# USB0_VBP2APB_WRAP_CONTROLLER_VBP_CORE_ADDR_MAP register map
Vendor: Texas Instruments
Peripheral module from a debugger description file (folder J721S2).
Registers are 32-bit, access per field, reset 0x0 unless marked. A register's access mark holds for its fields unless they carry their own. Offsets are as the file gives them; lines under a group give offsets from that group; [hi:lo] are bit positions; {n}, {i} and the like mark numbered series; 'fields as' and 'values as' point back to an identical list; <NAME> marks a mode.

## USB0_VBP2APB_WRAP_CONTROLLER_VBP_CORE_ADDR_MAP (part 1 of 9)
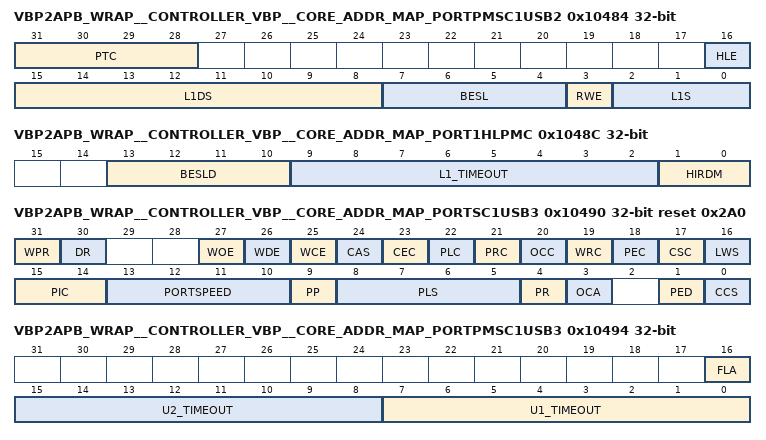
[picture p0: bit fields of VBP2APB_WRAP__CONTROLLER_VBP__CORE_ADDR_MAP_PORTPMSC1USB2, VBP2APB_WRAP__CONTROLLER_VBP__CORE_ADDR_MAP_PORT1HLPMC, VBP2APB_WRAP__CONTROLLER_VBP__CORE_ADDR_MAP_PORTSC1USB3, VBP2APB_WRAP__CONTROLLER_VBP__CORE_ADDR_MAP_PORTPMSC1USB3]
0x10484 VBP2APB_WRAP__CONTROLLER_VBP__CORE_ADDR_MAP_PORTPMSC1USB2 — The USB2 Port Power Management Status and Control register. Provides the USB2 LPM parameters necessary for the xHC to generate a LPM Token to the downstream device. This register may be read from or written to at any time, including whilst the CNR field in the USBSTS register is high.
  [31:28] PTC rw — Port Test Control, RW. Default = '0'. When this field is '0', the port is NOT operating in a test mode. A non-zero value indicates that it is operating in test mode and the specific test mode is indicated by the specific value. A non-zero Port Test Control value is only valid to a port that is in the Powered-Off state [PLS = Disabled]. If the port is not in this state, the xHC shall respond with the Port Test Control field set to Port Test Control Error. Refer to section 4.19.6 for the operational model for using these test modes. The encoding of the Test Mode bits for a USB2 protocol port are: 0: Test mode not enabled 1: Test J_STATE 2: Test K_STATE 3: Test SE0_NAK 4: Test Packet 5: Test FORCE_ENABLE 6-14: Reserved. 15: Port Test Control Error. Refer to the sections 7.1.20 and 11.24.2.13 of the USB2 spec for more information on Test Modes.
  [16] HLE rw — Hardware LPM Enable [HLE], RW. Default = '0'. If this bit is set to '1', then hardware controlled LPM shall be enabled for this port. Refer to section 4.23.5.1.1.1 of xHCI specification. If the USB2 Hardware LPM Capability is not supported [HLC = '0'] this field shall be RsvdZ.
  [15:8] L1DS rw — L1 Device Slot, RW. Default = 0. System software sets this field to indicate the ID of the Device Slot associated with the device directly attached to the Root Hub port. A value of '0' indicates no device is present. The xHC uses this field to lookup information necessary to generate the LPM Token packet.
  [7:4] BESL rw — Best Effort Service Latency [BESL], RW. Default = 0. System software sets this field to indicate to the recipient device how long the xHC will drive resume if it [the xHC] initiates an exit from L1. The BESL value encoding is defined in Table 13. Note that the BESL field is used by both software and hardware controlled LPM. Refer to section 4.23.5.1.1 of xHCI specification for more information on BESL use. Refer to section 5.2.5 of xHCI specification for information on how DBESL may be used to establish an initial value for BESL.
  [3] RWE rw — Remote Wake Enable [RWE], RW. Default = '0'. System software sets this flag to enable or disable the device for remote wake from L1. The value of this flag shall temporarily [while in L1] override the current setting of the Remote Wake feature set by the standard Set/ClearFeature[] commands defined in Universal Serial Bus Specification, revision 2.0, Chapter 9.
  [2:0] L1S ro — L1 Status [L1S], RO. Default = 0. This field is used by software to determine whether an L1-based suspend request [LPM transaction] was successful, specifically: 0: Invalid - This field shall be ignored by software. 1: Success - Port successfully transitioned to L1 [ACK] 2: Not Yet - Device is unable to enter L1 at this time [NYET] 3: Not Supported - Device does not support L1 transitions [STALL] 4: Timeout/Error - Device failed to respond to the LPM Transaction or an error occurred 5-7: Reserved The value of this field is only valid when the port resides in the L0 or L1 state [PLS = 0 or 2]. Refer to section 4.23.5.1.1 of xHCI specification for more information.
0x10488 VBP2APB_WRAP__CONTROLLER_VBP__CORE_ADDR_MAP_RSVDP1USB2 ro — Reserved and Preserved: Reserved for future RW implementations. Software shall preserve the value read for writes to bits.
0x1048C VBP2APB_WRAP__CONTROLLER_VBP__CORE_ADDR_MAP_PORT1HLPMC — The optional normative USB2 Port Hardware LPM Control register provides the USB2 LPM parameters necessary for the xHC to automatically generate a LPM Token to the downstream device. Refer to section 4.23.5.1.1.1 of xHCI specification for more information. This register may be read from or written to at any time, including whilst the CNR field in the USBSTS register is high.
  [13:10] BESLD rw — Best Effort Service Latency Deep [BESLD], RWS. Default = '0'. System software sets this field to indicate to the recipient device how long the xHC will drive resume on an exit from U2. Refer to section 4.23.5.1.1.1 of xHCI specification for more information on BESLD use. The BESLD value encoding is defined in Table 13. Refer to section 5.2.6 of xHCI specification for information on how DBESLD may be used to establish an initial value for BESLD.
  [9:2] L1_TIMEOUT rw — L1 Timeout, RWS. Default = 00h. Timeout value for the L1 inactivity timer [LPM Timer]. This field shall be set to 00h by the assertion of PR to '1'. Refer to section 4.23.5.1.1.1 of xHci specification for more information on L1 Timeout operation. The following are permissible values: 00h 128 us. [default] 01h 256 us. 02h 512 us. 03h 768 us. ... FFh 65,280 us.
  [1:0] HIRDM rw — Host Initiated Resume Duration Mode [HIRDM], RWS. Default = 0h. Indicates which HIRD value should be used. The following are permissible values: 0: Initiate L1 using BESL only on timeout. [default] 1: Initiate L1 using BESLD on timeout. If rejected by device, initiate L1 using BESL. 3-2: Reserved.
0x10490 VBP2APB_WRAP__CONTROLLER_VBP__CORE_ADDR_MAP_PORTSC1USB3 access not given reset 0x2A0 — Port Status and Control Register for USB3 protocol port. The register cannot be accessed if USB3 PHY is not active (i.e. when there is no USB3 PHY or when USB3 PHY has not started providing USB3 PIPE PCLK after reset).
  [31] WPR — Warm Port Reset [WPR], RW1S. Default = '0'. When software writes a '1' to this bit, the Warm Reset sequence as defined in the USB3 Specification is initiated and the PR flag is set to '1'. Once initiated, the PR, PRC, and WRC flags shall reflect the progress of the Warm Reset sequence. This flag shall always return 0 when read. Refer to section 4.19.5.1 of xHCI specification. (access R/W1TS)
  [30] DR ro — Device Removable [DR], RO. This flag indicates if this port has a removable device attached. '0' = Device is removable. '1' = Device is non-removable.
  [27] WOE rw — Wake on Over-current Enable [WOE], RWS. Default = '0'. Writing this bit to a '1' enables the port to be sensitive to over-current conditions as system wake-up events. Refer to section 4.15 of xHCI specification for operational model.
  [26] WDE rw — Wake on Disconnect Enable [WDE], RWS. Default = '0'. Writing this bit to a '1' enables the port to be sensitive to device disconnects as system wake-up events. Refer to section 4.15 of xHCI specification for operational model.
  [25] WCE rw — Wake on Connect Enable [WCE], RWS. Default = '0'. Writing this bit to a '1' enables the port to be sensitive to device connects as system wake-up events. Refer to section 4.15 of xHCI specification for operational model.
  [24] CAS ro — Cold Attach Status [CAS], RO. Default = '0'. '1' = Far-end Receiver Terminations were detected in the Disconnected state and the Root Hub Port State Machine was unable to advance to the Enabled state. Refer to sections 4.19.8 of xHCI specification for more details on the Cold Attach Status [CAS] assertion conditions. Software shall clear this bit by writing a '1' to WPR or the xHC shall clear this bit if CCS transitions to '1'. This flag is 0 if PP is 0 or for USB2 protocol ports. Note: Additionally to the xHCI spec the CAS may be set in D1/D2 state. If customer's PLL lock time ensures finishing LFPS in tPollingLFPSTimeout [360ms] the SW driver may ignore the CAS and wait for PORTSC.CCS. It prevents additional reset on USB port. However, handling CAS in normal way should not have any negative impact on the device.
  [23] CEC — Port Config Error Change [CEC], RW1CS. Default = '0'. This flag indicates that the port failed to configure its link partner. '0' = No change. '1' = Port Config Error detected. Software shall clear this bit by writing a '1' to it. Refer to section 4.19.2 of xHCI specification for more information on change bit usage. (access R/W1TC)
  [22] PLC — Port Link State Change [PLC], RW1CS. Default = '0'. This flag is set to '1' due to the following PLS transitions: U3 -> Resume [Wakeup signaling from a device], Resume -> Recovery -> U0 [Device Resume complete [USB3 protocol ports only]], Resume -> U0 [Device Resume complete [USB2 protocol ports only]], U3 -> Recovery -> U0 [Software Resume complete [USB3 protocol ports only]], U3 -> U0 [Software Resume complete [USB2 protocol ports only]], U2 -> U0 [L1 Resume complete [USB2 protocol ports only]], U0 -> U0 [L1 Entry Reject [USB2 protocol ports only]], Any state -> Inactive [Error [USB3 protocol ports only]]. Note that this flag shall not be set if the PLS transition was due to software setting PP to 0. Refer to section 4.23.5 of xHCI specification for more information. '0' = No change. '1' = Link Status Changed. Software shall clear this bit by writing a '1' to it. Refer to PLC Condition: references in section 4.19.1 for the specific port state transitions that set this flag. Refer to section 4.19.2 of xHCI specification for more information on change bit usage. (access R/W1TC)
  [21] PRC — Port Reset Change [PRC], RW1CS. Default = '0'. This flag is set to '1' due to a '1' to '0' transition of Port Reset [PR], e.g. when any reset processing [Warm or Hot] on this port is complete. Note that this flag shall not be set to '1' if the reset processing was forced to terminate due to software clearing PP or PED to '0'. '0' = No change. '1' = Reset complete. Software shall clear this bit by writing a '1' to it. Refer to section 4.19.5 of xHCI specification. Refer to section 4.19.2 of xHCI specification for more information on change bit usage. (access R/W1TC)
  [20] OCC — Over-current Change [OCC], RW1CS. Default = '0'. This bit shall be set to a '1' when there is a '0' to '1' or '1' to '0' transition of Over-current Active [OCA]. Software shall clear this bit by writing a '1' to it. Refer to section 4.19.2 of xHCI specification for more information on change bit usage. (access R/W1TC)
  [19] WRC — Warm Port Reset Change [WRC], RW1CS. Default = '0'. This bit is set when Warm Reset processing on this port completes. '0' = No change. '1' = Warm Reset complete. Note that this flag shall not be set to '1' if the Warm Reset processing was forced to terminate due to software clearing PP or PED to '0'. Software shall clear this bit by writing a '1' to it. Refer to section 4.19.5.1 of xHCI specification. Refer to section 4.19.2 of xHCI specification for more information on change bit usage. (access R/W1TC)
  [18] PEC — Port Enabled/Disabled Change [PEC], RW1CS. Default = '0'. '1' = change in PED. '0' = No change. Note that this flag shall not be set if the PED transition was due to software setting PP to '0'. Software shall clear this bit by writing a '1' to it. Refer to section 4.19.2 of xHCI specification for more information on change bit usage. This bit shall never be set to '1'. (access R/W1TC)
  [17] CSC — Connect Status Change [CSC], RW1CS. Default = '0'. '1' = Change in CCS. '0' = No change. This flag indicates a change has occurred in the ports Current Connect Status [CCS] or Cold Attach Status [CAS] bits. Note that this flag shall not be set if the CCS transition was due to software setting PP to '0', or the CAS transition was due to software setting WPR to '1'. The xHC sets this bit to '1' for all changes to the port device connect status, even if system software has not cleared an existing Connect Status Change. For example, the insertion status changes twice before system software has cleared the changed condition, root hub hardware will be setting an already-set bit [i.e., the bit will remain 1]. Software shall clear this bit by writing a '1' to it. Refer to section 4.19.2 of xHCI specification for more information on change bit usage. (access R/W1TC)
  [16] LWS rw — Port Link State Write Strobe [LWS], RW. Default = '0'. When this bit is set to '1' on a write reference to this register, this flag enables writes to the PLS field. When '0', write data in PLS field is ignored. Reads to this bit return '0'.
  [15:14] PIC rw — Port Indicator Control [PIC], RWS. Default = '0'. Writing to these bits has no effect if the Port Indicators [PIND] bit in the HCCPARAMS register is a '0'. If PIND bit is a '1', then the bit encodings are: 0: Port indicators are off, 1: Amber, 2: Green, 3: Undefined. This field is '0' if PP is '0'.
  [13:10] PORTSPEED ro — Port Speed [Port Speed], ROS. Default = '0'. This field identifies the speed of the connected USB Device. This field is only relevant if a device is connected [CCS = '1'] in all other cases this field shall indicate Undefined Speed. Possible values: 0: Undefined Speed 1-15: Protocol Speed ID [PSI], refer to section 7.2.1 of xHCI specification for the definition of PSIV field in the PSI Dword.
  [9] PP rw — Port Power [PP], RWS. Default = '1'. This flag reflects a port's logical, power control state. Because host controllers can implement different methods of port power switching, this flag may or may not represent whether [VBus] power is actually applied to the port. When PP equals a '0' the port is nonfunctional and shall not report attaches, detaches, or Port Link State [PLS] changes. However, the port shall report over-current conditions when PP = '0' if PPC = '0'. After modifying PP, software shall read PP and confirm that it has reached its target state before modifying it again, undefined behavior may occur if this procedure is not followed. '0' = This port is in the Powered-off state. '1' = This port is not in the Powered-off state. If the Port Power Control [PPC] flag in the HCCPARAMS register is '1', then xHC has port power control switches and this bit represents the current setting of the switch ['0' = off, '1'=on]. If the Port Power Control [PPC] flag in the HCCPARAMS register is '0', then xHC does not have port power control switches and each port is hard wired to power, and not affected by this bit. When an over-current condition is detected on a powered port, the xHC shall transition the PP bit in each affected port from a '1' to '0' [removing power from the port]. Refer to section 4.19.4 for more information.
  [8:5] PLS rw — Port Link State [PLS], RWS. Default = RxDetect ['5']. This field is used to power manage the port and reflects its current link state. When the port is in the Enabled state, system software may set the link U state by writing this field. System software may also write this field to force a Disabled to Disconnected state transition of the port. Write Values: 0: The link shall transition to a U0 state from any of the U states. 3: The link shall transition to a U3 state from the U0 state. This action selectively suspends the device connected to this port. While the Port Link State = U3, the hub does not propagate downstream-directed traffic to this port, but the hub shall respond to resume signaling from the port. 5: If the port is in the Disabled state [PLS = Disabled, PP = '1'], then the link shall transition to a RxDetect state and the port shall transition to the Disconnected state, else ignored. 1-2,4,6-15: Ignored. State Encoding: 0: Link is in the U0 State, 1: Link is in the U1 State, 2: Link is in the U2 State, 3: Link is in the U3 State [Device Suspended], 4: Link is in the Disabled State, 5: Link is in the RxDetect State, 6: Link is in the Inactive State, 7: Link is in the Polling State, 8: Link is in the Recovery State, 9: Link is in the Hot Reset State, 10 Link is in the Compliance Mode State, 11: Link is in the Test Mode State, 12-14: Reserved, 15: Link is in the Resume State. Note: The Port Link State Write Strobe [LWS] shall also be set to '1' to write this field. This field is undefined if PP = '0'. Note: Transitions between different states are not reflected until the transition is complete. Refer to section 4.19 of xHCI specification for PLS transition conditions. Refer to sections 4.15.2 and 4.23.5 for more information on the use of this field.
  [4] PR — Port Reset [PR], RW1S. Default = '0'. '1' = Port Reset signaling is asserted. '0' = Port is not in Reset. When software writes a '1' to this bit generating a '0' to '1' transition, the bus reset sequence is initiated. USB3 protocol ports shall execute the Hot Reset sequence as defined in the USB3 Spec. PR remains set until reset signaling is completed by the root hub. This flag is '0' if PP is '0'. (access R/W1TS)
  [3] OCA ro — Over-current Active [OCA], RO. Default = '0'. '1' = This port currently has an over-current condition. '0' = This port does not have an over-current condition. This bit shall automatically transition from a '1' to a '0' when the over-current condition is removed.
  [1] PED — Port Enabled/Disabled [PED], RW1CS. Default = '0'. '1' = Enabled. '0' = Disabled. Ports may only be enabled by the xHC. Software cannot enable a port by writing a '1' to this flag. A port may be disabled by software writing a '1' to this flag. This flag shall automatically be cleared to '0' by a disconnect event or other fault condition. Note that the bit status does not change until the port state actually changes. There may be a delay in disabling or enabling a port due to other host controller or bus events. When the port is disabled [PED = '0'] downstream propagation of data is blocked on this port, except for reset. When the port is in the Polling state [after detecting an attach], the port shall automatically transition to the Enabled state and set PED to '1' upon the completion of successful link training. When the port is in the Disabled state, software shall write a 5 [RxDetect] to the PLS field to transition the port to the Disconnected state. Refer to section 4.19.1.2 of xHCI specification. PED shall automatically be cleared to '0' when PR is set to '1', and set to '1' when PR transitions from '1' to '0' after a successful reset. Refer to Port Reset [PR] bit for more information on how the PED bit is managed. Note that when software writes this bit to a '1', it shall also write a '0' to the PR bit. This flag is '0' if PP is '0'. (access R/W1TC)
  [0] CCS ro — Current Connect Status [CCS], ROS. Default = '0'. '1' = A device is connected to the port. '0' = A device is not connected. This value reflects the current state of the port, and may not correspond directly to the event that caused the Connect Status Change [CSC] bit to be set to '1'. Refer to sections 4.19.3 and 4.19.4 of xHCI specification for more details on the Connect Status Change [CSC] assertion conditions. This flag is '0' if PP is '0'.
0x10494 VBP2APB_WRAP__CONTROLLER_VBP__CORE_ADDR_MAP_PORTPMSC1USB3 — USB3 Port Power Management Status and Control register. Controls the SuperSpeed USB link U-State timeouts. The register cannot be accessed if USB3 PHY is not active (i.e. when there is no USB3 PHY or when USB3 PHY has not started providing USB3 PIPE PCLK after reset).
  [16] FLA rw — Force Link PM Accept [FLA], RW. Default = '0'. When this bit is set to '1', the port shall generate a Set Link Function LMP with the Force_LinkPM_Accept bit asserted ['1']. When this bit is cleared to '0', the port shall generate a Set Link Function LMP with the Force_LinkPM_Accept bit de-asserted ['0']. This flag shall be set to '0' by the assertion of PR to '1' or when CCS = transitions from '0' to '1'. Writes to this flag have no effect if PP = '0'. The Set Link Function LMP is sent by the xHC to the device connected on this port when this bit transitions from '0' to '1' or '1' to '0'. Refer to Sections 8.4.2 and 10.14.2.2 of the USB3 specification for more details. Improper use of the SS Force_LinkPM_Accept functionality can impact the performance of the link significantly. This bit shall only be used for compliance and testing purposes. Software shall ensure that there are no pending packets at the link level before setting this bit. This flag is '0' if PP is '0'.
  [15:8] U2_TIMEOUT rw — U2 Timeout, RWS. Default = 0. Timeout value for U2 inactivity timer. If equal to FFh, the port is disabled from initiating U2 entry. This field shall be set to '0' by the assertion of PR to '1'. Refer to section 4.19.4.1 of xHCI specification for more information on U2 Timeout operation. The following are permissible values: 00h Zero [default] 01h 256 us 02h 512 us ... FEh 65,.024 ms FFh Infinite A U2 Inactivity Timeout LMP shall be sent by the xHC to the device connected on this port when this field is written. Refer to Sections 8.4.3 and 10.4.2.10 of the USB3 specification for more details.
  [7:0] U1_TIMEOUT rw — U1 Timeout, RWS. Default = 0. Timeout value for U1 inactivity timer. If equal to FFh, the port is disabled from initiating U1 entry. This field shall be set to '0' by the assertion of PR to '1'. Refer to section 4.19.4.1 of xHCI specification for more information on U1 Timeout operation. The following are permissible values: 00h Zero [default] 01h 1 us. 02h 2 us. ... 7Fh 127 us. 80h - FEh Reserved FFh Infinite
0x10498 VBP2APB_WRAP__CONTROLLER_VBP__CORE_ADDR_MAP_PORTLI1 ro — The USB3 Port Link Info register reports the Link Error Count.
  [15:0] LEC — Link Error Count, RO. Default = '0'. This field returns the number of link errors detected by the port. This value shall be reset to '0' by the assertion of a Chip Hardware Reset, HCRST, when PR transitions from 1 to 0, or when CCS = transitions from '0' to '1'.
0x1049C VBP2APB_WRAP__CONTROLLER_VBP__CORE_ADDR_MAP_RSVDP1USB3 ro — Reserved and Preserved: Reserved for future RW implementations. Software shall preserve the value read for writes to bits.
0x12000 VBP2APB_WRAP__CONTROLLER_VBP__CORE_ADDR_MAP_MFINDEX ro — This register is used by the system software to determine the current periodic frame. The register value is incremented every 125 microseconds (once each microframe). This register is only incremented while Run/Stop (R/S) = '1'. The value of this register affects the SOF value generated by USB2 Bus Instances.
  [13:0] MFINDEX — Microframe Index, RO. The value in this register increments at the end of each microframe [e.g. 125us.]. Bits [13:3] may be used to determine the current 1ms Frame Index. Note: Setting frindex_wr_en to '1' [bit 31 of XECP_CMDM_CTRL_REG3] enables software writes to this field.
0x12004 VBP2APB_WRAP__CONTROLLER_VBP__CORE_ADDR_MAP_RSVDZ_RT ro — Reserved and Zero: Reserved for future RW1C implementations. Software shall use zero for writes to these bits.
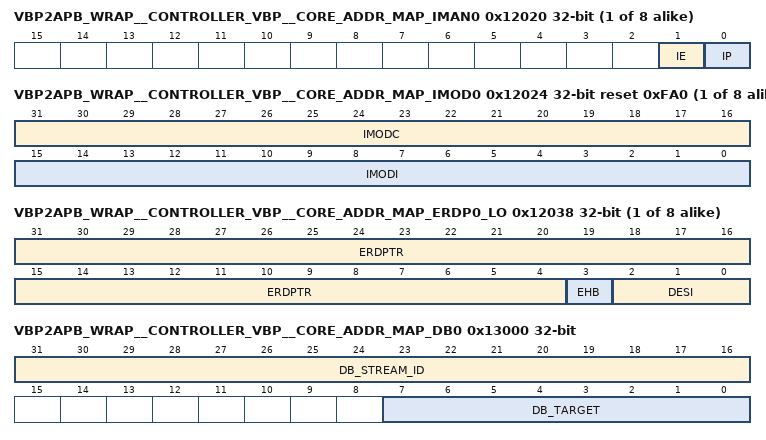
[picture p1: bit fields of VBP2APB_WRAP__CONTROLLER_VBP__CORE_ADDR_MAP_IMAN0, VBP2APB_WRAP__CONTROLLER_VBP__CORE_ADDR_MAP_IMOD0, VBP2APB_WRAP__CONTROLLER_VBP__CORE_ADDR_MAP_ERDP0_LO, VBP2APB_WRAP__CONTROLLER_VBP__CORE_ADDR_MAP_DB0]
{0x12020+0x20*i} VBP2APB_WRAP__CONTROLLER_VBP__CORE_ADDR_MAP_IMAN{i} access not given (i=0..7) — Interrupter Management Register (IMAN). The Interrupter Management register allows system software to enable, disable, detect, and force xHC interrupts.
  [1] IE rw — Interrupt Enable [IE], RW. Default = '0'. This flag specifies whether the Interrupter is capable of generating an interrupt. When this bit and the IP bit are set ['1'], the Interrupter shall generate an interrupt when the Interrupter Moderation Counter reaches 0. If this bit is '0', then the Interrupter is prohibited from generating interrupts.
  [0] IP — Interrupt Pending [IP], RW1C. Default = '0'. This flag represents the current state of the Interrupter. If IP = '1', an interrupt is pending for this Interrupter. A '0' value indicates that no interrupt is pending for the Interrupter. Refer to section 4.17.5 of the xHCI specification for the conditions that modify the state of this flag. (access R/W1TC)
{0x12024+0x20*i} VBP2APB_WRAP__CONTROLLER_VBP__CORE_ADDR_MAP_IMOD{i} rw reset 0xFA0 (i=0..7) — Interrupter Moderation Register (IMOD). The Interrupter Moderation Register controls the interrupt moderation feature of an Interrupter, allowing system software to throttle the interrupt rate generated by the xHC.
  [31:16] IMODC — Interrupt Moderation Counter [IMODC], RW. Default = undefined. Down counter. Loaded with the IMODI value whenever IP is cleared to '0', counts down to 0, and stops. The associated interrupt shall be signaled whenever this counter is zero, the Event Ring is not empty, the IE and IP flags = '1', and EHB = '0'. This counter may be directly written by software at any time to alter the interrupt rate.
  [15:0] IMODI — Interrupt Moderation Interval [IMODI], RW. Default = 'hFA0' [~1ms]. Minimum inter-interrupt interval. The interval is specified in 250ns increments. A value of zero disables interrupt throttling logic and interrupts shall be generated immediately if IP = '0', EHB = '0', and the Event Ring is not empty. The IMODI field shall default to 'hFA0' [1 ms] upon initialization and reset. It may be loaded with an alternative value by software when the Interrupter is initialized.
{0x12028+0x20*i} VBP2APB_WRAP__CONTROLLER_VBP__CORE_ADDR_MAP_ERSTSZ{i} (i=0..7) — Event Ring Segment Table Size Register (ERSTSZ). The Event Ring Segment Table Size Register defines the number of segments supported by the Event Ring Segment Table.
  [15:0] ERSTS rw — Event Ring Segment Table Size, RW. Default = 0. This field identifies the number of valid Event Ring Segment Table entries in the Event Ring Segment Table pointed to by the Event Ring Segment Table Base Address register. The maximum value supported by an xHC implementation for this register is defined by the ERST Max field in the HCSPARAMS2 register. For Secondary Interrupters: Writing a value of 0 to this field disables the Event Ring. Any events targeted at this Event Ring when it is disabled shall result in undefined behavior of the Event Ring. For the Primary Interrupter: Writing a value of 0 to this field shall result in undefined behavior of the Event Ring. The Primary Event Ring cannot be disabled.
{0x1202C+0x20*i} VBP2APB_WRAP__CONTROLLER_VBP__CORE_ADDR_MAP_reserved{i} ro (i=0..7) — Reserved
{0x12030+0x20*i} VBP2APB_WRAP__CONTROLLER_VBP__CORE_ADDR_MAP_ERSTBA{i}_LO (i=0..7) — The Event Ring Segment Table Base Address Register identifies the start address of the Event Ring Segment Table.
  [31:6] ERSTBADDR_LO rw — Event Ring Segment Table Base Address Register, RW. Default = 0. This field defines the low order bit [25:0] of the start address of the Event Ring Segment Table [the address is 58 bits wide] . Writing this register sets the Event Ring State Machine: EREP Advancement to the Start state. This field shall not be modified if HCHalted [HCH] = '0'.
{0x12034+0x20*i} VBP2APB_WRAP__CONTROLLER_VBP__CORE_ADDR_MAP_ERSTBA{i}_HI rw (i=0..7) — The Event Ring Segment Table Base Address Register identifies the start address of the Event Ring Segment Table.
  [31:0] ERSTBADDR_HI — Event Ring Segment Table Base Address Register, RW. Default = 0. This field defines the high order bits [57:26] of the start address of the Event Ring Segment Table [the address is 58 bits wide] . Writing this register sets the Event Ring State Machine:EREP Advancement to the Start state. Refer to Figure 20 in xHCI specificationfor more information. This field shall not be modified if HCHalted [HCH] = '0'.
{0x12038+0x20*i} VBP2APB_WRAP__CONTROLLER_VBP__CORE_ADDR_MAP_ERDP{i}_LO access not given (i=0..7) — Event Ring Dequeue Pointer Register (ERDP). The Event Ring Dequeue Pointer Register is written by software to define the Event Ring Dequeue Pointer location to the xHC. Software updates this pointer when it has finished the evaluation of an Event(s) on the Event Ring.
  [31:4] ERDPTR rw — Event Ring Dequeue Pointer, RW. Default = 0. This field defines the 28 low order bits of the 64-bit address of the current Event Ring Dequeue Pointer.
  [3] EHB — Event Handler Busy [EHB], RW1C. Default = '0'. This flag shall be set to '1' when the IP bit is set to '1' and cleared to '0' by software when the Dequeue Pointer register is written. Refer to section 4.17.2 of xHCI specification for more information (access R/W1TC)
  [2:0] DESI rw — Dequeue ERST Segment Index [DESI]. Default = 0. This field may be used by the xHC to accelerate checking the Event Ring full condition. This field is written with the low order 3 bits of the offset of the ERST entry which defines the Event Ring segment that the Event Ring Dequeue Pointer resides in.
{0x1203C+0x20*i} VBP2APB_WRAP__CONTROLLER_VBP__CORE_ADDR_MAP_ERDP{i}_HI rw (i=0..7) — Event Ring Dequeue Pointer Register (ERDP). The Event Ring Dequeue Pointer Register is written by software to define the Event Ring Dequeue Pointer location to the xHC. Software updates this pointer when it has finished the evaluation of an Event(s) on the Event Ring.
  [31:0] ERDPTR_HI — Event Ring Dequeue Pointer, RW. Default = 0. This field defines the 32 high order bits of the 64-bit address of the current Event Ring Dequeue Pointer.
0x13000 VBP2APB_WRAP__CONTROLLER_VBP__CORE_ADDR_MAP_DB0 — Host Controller Doorbell. The Doorbell Array is organized as an array of up to 256 Doorbell Registers. One 32-bit Doorbell Register is defined in the array for each Device Slot. System software utilizes the Doorbell Register to notify the xHC that it has Device Slot related work for the xHC to perform. The number of Doorbell Registers implemented by a particular instantiation of a host controller is documented in the Number of Device Slots (MaxSlots) field of the HCSPARAMS1 register (section 5.3.3 of xHCI specification). These registers are pointed to by the Doorbell Offset Register (DBOFF) in the xHC Capability register space. The Doorbell Array base address shall be Dword aligned and is calculated by adding the value in the DBOFF register (section 5.3.7 of xHCI specification) to Base (the base address of the xHCI Capability register address space). Doorbell Register 0 is dedicated to the Host Controller.
  [31:16] DB_STREAM_ID rw — DB Stream ID, RW. Doorbell Stream ID. If the endpoint of a Device Context Doorbell defines Streams, then this field shall be used to identify which Stream of the endpoint the doorbell reference is targeting. System software is responsible for ensuring that the value written to this field is valid. If the endpoint defines Streams [MaxPStreams > 0], then 0, 65535 [No Stream] and 65534 [Prime] are reserved Stream ID values and shall not be written to this field. If the endpoint does not define Streams [MaxPStreams = 0] and a non-'0' value is written to this field, the doorbell reference shall be ignored. This field only applies to Device Context Doorbells and shall be cleared to zero for Host Controller Command Doorbells. This field returns zero when read.
  [7:0] DB_TARGET rw — DB Target, RW. Doorbell Target. This field defines the target of the doorbell reference. The table below defines the xHC notification that is generated by ringing the doorbell. Note that Doorbell Register 0 is dedicated to Command Ring and decodes this field differently than the other Doorbell Registers. Possible values [ For this register, there is only one valid value for the DB Target field, 0 [Host Controller Command]. The remaining values [1-255] are reserved.]: 0: Command Doorbell 1:247 Reserved 248:255 Vendor Defined This field returns zero when read and should be treated as undefined by software. When the Command Doorbell is written, the DB Stream ID field shall be cleared to zero.
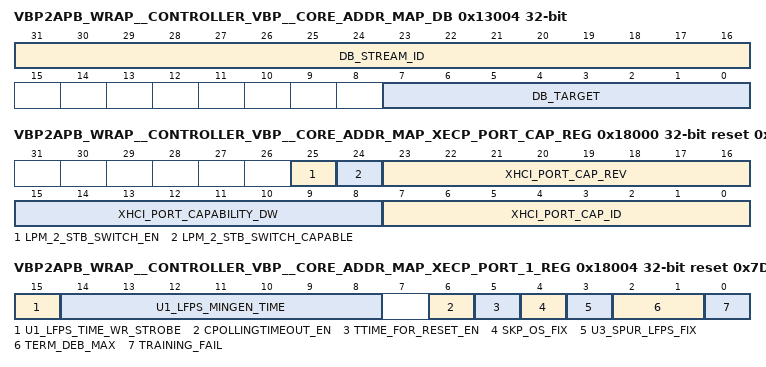
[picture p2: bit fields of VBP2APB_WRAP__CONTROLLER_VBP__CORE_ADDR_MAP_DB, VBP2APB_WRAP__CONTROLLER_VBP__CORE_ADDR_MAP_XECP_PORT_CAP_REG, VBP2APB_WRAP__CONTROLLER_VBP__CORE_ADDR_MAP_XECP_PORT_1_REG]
0x13004 VBP2APB_WRAP__CONTROLLER_VBP__CORE_ADDR_MAP_DB — The Doorbell Array is organized as an array of up to 256 Doorbell Registers. One 32-bit Doorbell Register is defined in the array for each Device Slot. System software utilizes the Doorbell Register to notify the xHC that it has Device Slot related work for the xHC to perform. The number of Doorbell Registers implemented by a particular instantiation of a host controller is documented in the Number of Device Slots (MaxSlots) field of the HCSPARAMS1 register (section 5.3.3 of xHCI specification). These registers are pointed to by the Doorbell Offset Register (DBOFF) in the xHC Capability register space. The Doorbell Array base address shall be Dword aligned and is calculated by adding the value in the DBOFF register (section 5.3.7 of xHCI specification) to Base (the base address of the xHCI Capability register address space).
  [31:16] DB_STREAM_ID rw — DB Stream ID, RW. Doorbell Stream ID. If the endpoint of a Device Context Doorbell defines Streams, then this field shall be used to identify which Stream of the endpoint the doorbell reference is targeting. System software is responsible for ensuring that the value written to this field is valid. If the endpoint defines Streams [MaxPStreams > 0], then 0, 65535 [No Stream] and 65534 [Prime] are reserved Stream ID values and shall not be written to this field. If the endpoint does not define Streams [MaxPStreams = 0] and a non-'0' value is written to this field, the doorbell reference shall be ignored. This field only applies to Device Context Doorbells and shall be cleared to zero for Host Controller Command Doorbells. This field returns zero when read.
  [7:0] DB_TARGET rw — DB Target, RW. Doorbell Target. This field defines the target of the doorbell reference. The table below defines the xHC notification that is generated by ringing the doorbell. Possible values: 0: Reserved 1: Control EP 0 Enqueue Pointer Update 2: EP 1 OUT Enqueue Pointer Update 3: EP 1 IN Enqueue Pointer Update 4: EP 2 OUT Enqueue Pointer Update 5: EP 2 IN Enqueue Pointer Update ... 30: EP 15 OUT Enqueue Pointer Update 31: EP 15 IN Enqueue Pointer Update 32:247: Reserved 248:255: Vendor Defined This field returns zero when read and should be treated as undefined by software. When the Command Doorbell is written, the DB Stream ID field shall be cleared to zero.
0x18000 VBP2APB_WRAP__CONTROLLER_VBP__CORE_ADDR_MAP_XECP_PORT_CAP_REG reset 0x10102C3 — Extended capability for USB 3.0 Port. This register may be read from or written to at any time, including whilst the CNR field in the USBSTS register is high. This is a vendor defined capability. This register is reserved. This register should not be modified by software. It is described only for informative purposes.
  [25] LPM_2_STB_SWITCH_EN rw — Enable switching to stb_clk.
  [24] LPM_2_STB_SWITCH_CAPABLE ro — xHC is capable of switching to stb_clk.
  [23:16] XHCI_PORT_CAP_REV ro — XHCI_PORT_CAP_REV : revision of the Port Capability structure .
  [15:8] XHCI_PORT_CAPABILITY_DW ro — XHCI_PORT_CAPABILITY_DW. Next Item Pointer. This field provides an offset pointing to the location of next item in the functions capability list.
  [7:0] XHCI_PORT_CAP_ID ro — XHCI_PORT_CAP_ID. Port capability ID.
0x18004 VBP2APB_WRAP__CONTROLLER_VBP__CORE_ADDR_MAP_XECP_PORT_1_REG access not given reset 0x7D40 — Extended capability for USB 3.0 Port. This register may be read from or written to at any time, including whilst the CNR field in the USBSTS register is high. This is a vendor defined capability. This register is reserved. This register should not be accessed by software. It is described only for informative purposes.
  [15] U1_LFPS_TIME_WR_STROBE rw — Minimum U1 LFPS generation time write stobe. Returns '0' when read.
  [14:8] U1_LFPS_MINGEN_TIME rw — Minimum U1 LFPS generation time. Written only if U1_LFPS_TIME_WR_STROBE is 1.
  [6] CPOLLINGTIMEOUT_EN rw — Enable cPollingTimeout
  [5] TTIME_FOR_RESET_EN rw — Enable tTimeForResetError timer
  [4] SKP_OS_FIX rw — Change counting number of symbols for SKP OS insertion [only for the 1st SKP OS]
  [3] U3_SPUR_LFPS_FIX rw — Enable filtering out spurious LFPS when entering U3 state
  [2:1] TERM_DEB_MAX rw — Number of the consecutive lack of Far-end Rx Termination detected that causes transition from SS.Inactive to RxDetect state
  [0] TRAINING_FAIL — When reading: Link Polling training error flag status, When writing '1': clear the Link Polling training error flag, When writing '0': no effect (access R/W1TC)
